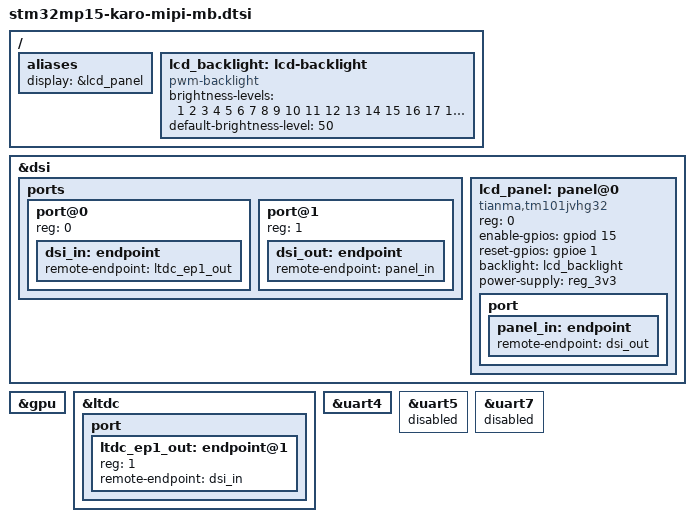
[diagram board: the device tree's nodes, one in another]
// SPDX-License-Identifier: (GPL-2.0 OR BSD-3-Clause)
/*
 * Copyright (C) 2020 Lothar Waßmann <LW@KARO-electronics.de>
 *
 */

/ {
	aliases {
		display = &lcd_panel;
	};

	lcd_backlight: lcd-backlight {
		compatible = "pwm-backlight";
		brightness-levels = < 1  2  3  4  5  6  7  8  9  10
				     11 12 13 14 15 16 17 18 19  20
				     21 22 23 24 25 26 27 28 29  30
				     31 32 33 34 35 36 37 38 39  40
				     41 42 43 44 45 46 47 48 49  50
				     51 52 53 54 55 56 57 58 59  60
				     61 62 63 64 65 66 67 68 69  70
				     71 72 73 74 75 76 77 78 79  80
				     81 82 83 84 85 86 87 88 89  90
				     91 92 93 94 95 96 97 98 99 100
				    >;
		default-brightness-level = <50>;
	};
};

&dsi {
	#address-cells = <1>;
	#size-cells = <0>;
	status = "okay";

	ports {
		#address-cells = <1>;
		#size-cells = <0>;

		port@0 {
			reg = <0>;
			dsi_in: endpoint {
				remote-endpoint = <&ltdc_ep1_out>;
			};
		};

		port@1 {
			reg = <1>;
			dsi_out: endpoint {
				remote-endpoint = <&panel_in>;
			};
		};
	};

	lcd_panel: panel@0 {
		compatible = "tianma,tm101jvhg32";
		reg = <0>;
		pinctrl-names = "default", "sleep";
		enable-gpios = <&gpiod 15 GPIO_ACTIVE_HIGH>;
		reset-gpios = <&gpioe 1 GPIO_ACTIVE_HIGH>;
		backlight = <&lcd_backlight>;
		power-supply = <&reg_3v3>;
		status = "okay";

		port {
			panel_in: endpoint {
				remote-endpoint = <&dsi_out>;
			};
		};
	};
};

&gpu {
	status = "okay";
};

&ltdc {
	status = "okay";

	port {
		#address-cells = <1>;
		#size-cells = <0>;

		ltdc_ep1_out: endpoint@1 {
			reg = <1>;
			remote-endpoint = <&dsi_in>;
		};
	};
};

&uart4 {
	/delete-property/ rts-gpios;
};

&uart5 {
	status = "disabled";
};

&uart7 {
	status = "disabled";
};
